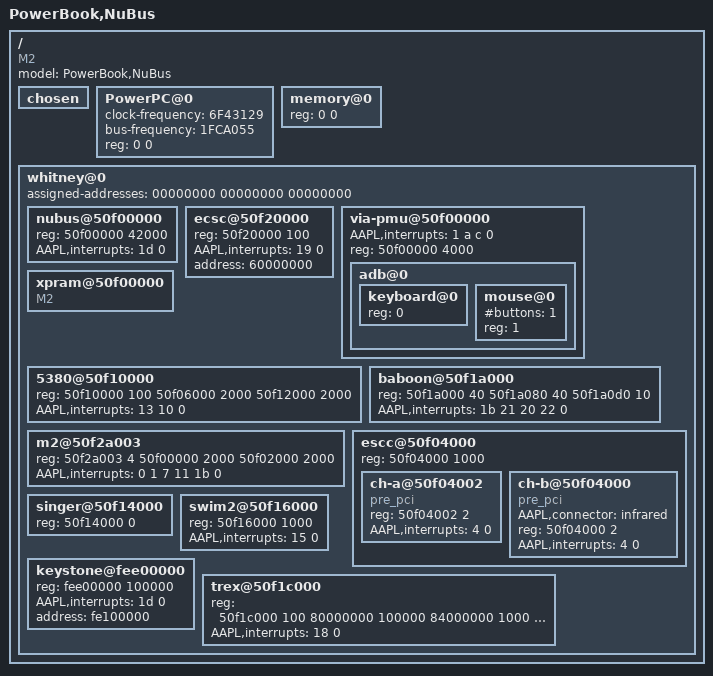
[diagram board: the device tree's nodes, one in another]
/*
 * NuBus PowerBook Device Tree Source
 */


/ {
	model = "PowerBook,NuBus";
	compatible = "M2","MacRISC";
	#address-cells = <1>;
	#size-cells = <1>;

	chosen {
	};

	PowerPC@0 {
		device_type = "cpu";
		clock-frequency = <6F43129>;
		bus-frequency = <1FCA055>;
		reg = <0 0>;
	};

	memory@0 {
		device_type = "memory";
		reg = <0 0>;
	};

	whitney@0 {
		device_type = "cpu-bus";
		#address-cells = <1>;
		#size-cells = <1>;
		/* a fake for early serial console */
		assigned-addresses = <00000000 00000000 00000000>;

	  	nubus@50f00000 {
			device_type = "nubus";
			reg = <50f00000 42000>;
			#address-cells = <1>;
			#size-cells = <1>;
			AAPL,interrupts = <1d 0>;
		};

		ecsc@50f20000 {
			device_type = "display";
			reg = <50f20000 100>;
			AAPL,interrupts = <19 0>;
			address = <60000000>;
		};

		via-pmu@50f00000 {
			device_type = "pmu";
			AAPL,interrupts = <1 a c 0>;
			reg = <50f00000 4000>;
		
			adb@0 {
				device_type = "adb";
				#address-cells = <1>;
				#size-cells = <0>;

				keyboard@0 {
					device_type = "keyboard";
					reg = <0>;
				};

				mouse@0 {
					device_type = "mouse";
					#buttons = <1>;
					reg = <1>;
				};
			};
		};

		xpram@50f00000 {
			device_type = "xpram";
			compatible = "M2";
		};

		5380@50f10000 {
			device_type = "scsi";
			reg = <50f10000 100 50f06000 2000 50f12000 2000>;
			AAPL,interrupts = <13 10 0>;
		};

		baboon@50f1a000 {
			device_type = "ATA";
			reg = <50f1a000 40 50f1a080 40 50f1a0d0 10>;
			AAPL,interrupts = <1b 21 20 22 0>;
		};

		m2@50f2a003 {
			device_type = "m2-pic";
			reg = <50f2a003 4 50f00000 2000 50f02000 2000>;
			AAPL,interrupts = <0 1 7 11 1b 0>;
		};

		escc@50f04000 {
			device_type = "escc";
			#address-cells = <1>;
			#size-cells = <1>;
			reg = <50f04000 1000>;

			ch-a@50f04002 {
				device_type = "serial";
				compatible = "pre_pci";
				reg = <50f04002 2>;
				AAPL,interrupts = <4 0>;
			};

			ch-b@50f04000 {
				device_type = "serial";
				compatible = "pre_pci";
				AAPL,connector = "infrared";
				reg = <50f04000 2>;
				AAPL,interrupts = <4 0>;
			};
		};

		singer@50f14000 {
			device_type = "sound";
			reg = <50f14000 0>;
		};

		swim2@50f16000 {
			device_type = "block";
			reg = <50f16000 1000>;
			AAPL,interrupts = <15 0>;
		};

		keystone@fee00000 {
			device_type = "display";
			reg = <fee00000 100000>;
			AAPL,interrupts = <1d 0>;
			address = <fe100000>;
		};

		trex@50f1c000 {
			device_type = "pcmcia";
			reg = <50f1c000 100 80000000 100000 84000000 1000 88000000 100000 8c000000 1000>;
			AAPL,interrupts = <18 0>;
		};
	};

};
